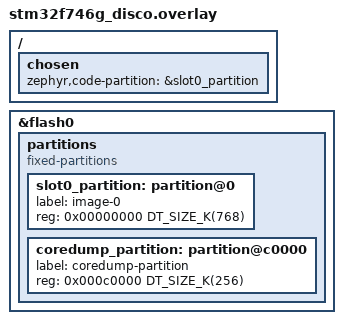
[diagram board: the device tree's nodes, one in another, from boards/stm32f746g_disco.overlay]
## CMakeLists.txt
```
cmake_minimum_required(VERSION 3.20.0)

if (EXISTS "${CMAKE_CURRENT_SOURCE_DIR}/credentials.conf")
    list(APPEND EXTRA_CONF_FILE "${CMAKE_CURRENT_SOURCE_DIR}/credentials.conf")
endif()

find_package(Zephyr REQUIRED HINTS $ENV{ZEPHYR_BASE})
project(stm32_cold_chain_monitor)

add_subdirectory(src/net ${CMAKE_CURRENT_BINARY_DIR}/src/net)

target_sources(app PRIVATE
        src/main.c
        src/fridge_monitor.c
        src/ui.c
        src/spotflow_logo.c
)
```

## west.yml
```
manifest:
  projects:
    # Zephyr RTOS - STMicroelectronics STM32F746G-DISCO
    - name: zephyr
      url: https://github.com/zephyrproject-rtos/zephyr
      revision: v4.4.0
      clone-depth: 1
      import:
        path-prefix: external
        name-allowlist:
          - cmsis
          - cmsis_6
          - hal_stm32
          - mbedtls
          - tf-psa-crypto
          - zcbor
          - lvgl

    - name: spotflow-device-sdk
      url: https://github.com/spotflow-io/device-sdk
      revision: main
      path: external/modules/lib/spotflow
```

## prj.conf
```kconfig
# Spotflow SDK
CONFIG_SPOTFLOW=y
CONFIG_SPOTFLOW_MODULE_DEFAULT_LOG_LEVEL=4

# Logging
CONFIG_LOG=y
CONFIG_LOG_BUFFER_SIZE=2048
CONFIG_LOG_RUNTIME_FILTERING=y
CONFIG_REQUIRES_FLOAT_PRINTF=y
CONFIG_LOG_FUNC_NAME_PREFIX_INF=y
CONFIG_LOG_FUNC_NAME_PREFIX_WRN=y
CONFIG_LOG_FUNC_NAME_PREFIX_ERR=y
CONFIG_SPOTFLOW_LOG_BACKEND_QUEUE_SIZE=16
CONFIG_SPOTFLOW_LOG_BUFFER_SIZE=256
CONFIG_SPOTFLOW_CBOR_LOG_MAX_LEN=512
CONFIG_HEAP_MEM_POOL_ADD_SIZE_SPOTFLOW_LOGGING=3072

# Metrics
CONFIG_SPOTFLOW_METRICS=y
CONFIG_SPOTFLOW_METRICS_SYSTEM=y
CONFIG_SPOTFLOW_METRICS_HEARTBEAT=y
CONFIG_SPOTFLOW_METRICS_HEARTBEAT_INTERVAL=60
CONFIG_HEAP_MEM_POOL_ADD_SIZE_SPOTFLOW_METRICS=6144

# Networking (Ethernet + DHCP; TLS/MQTT are pulled in by the Spotflow module)
CONFIG_NETWORKING=y
CONFIG_NET_MGMT=y
CONFIG_NET_MGMT_EVENT=y
CONFIG_NET_MGMT_EVENT_INFO=y
CONFIG_NET_CONFIG_AUTO_INIT=n
CONFIG_NET_CONNECTION_MANAGER=y
CONFIG_NET_DHCPV4=y
CONFIG_NET_IPV4=y
CONFIG_NET_IPV6=n
CONFIG_NET_TCP=y
CONFIG_NET_UDP=y

# Flash: enabled for the coredump partition backend (see boards/*.overlay).
#
# Spotflow config persistence (NVS/settings) is intentionally disabled on this
# board. The Spotflow config store initializes from the log backend before the
# kernel scheduler is running, and the STM32 QSPI flash that would hold the
# storage partition cannot service a blocking read that early (it returns
# -EDEADLK). Logs, metrics, and coredumps do not depend on persistence.
CONFIG_FLASH=y
CONFIG_FLASH_MAP=y
CONFIG_SPOTFLOW_SAMPLE_CONFIG_PERSISTENCE_FLASH=n

# Coredumps: captured to the internal-flash coredump partition on a fatal
# fault, then uploaded to Spotflow on the next boot over MQTT/TLS.
# CONFIG_SPOTFLOW_COREDUMPS selects DEBUG_COREDUMP, FLASH and REBOOT and
# defaults the backend to DEBUG_COREDUMP_BACKEND_FLASH_PARTITION. THREADS mode
# dumps thread stacks and metadata instead of the whole linker-defined RAM
# image, which keeps the dump well inside the 256 KiB partition.
CONFIG_SPOTFLOW_COREDUMPS=y
CONFIG_DEBUG_COREDUMP_THREADS_METADATA=y
CONFIG_DEBUG_COREDUMP_MEMORY_DUMP_THREADS=y
CONFIG_GPIO=y

# Constrain the application image to the code partition (first 768 KiB), leaving
# the last flash sector for coredumps (see boards/stm32f746g_disco.overlay).
CONFIG_USE_DT_CODE_PARTITION=y

# Local display: 4.3" LTDC LCD via LVGL v9 with FT5336 capacitive touch.
# The framebuffer lives in the external SDRAM (see the board devicetree).
CONFIG_DISPLAY=y
CONFIG_INPUT=y
CONFIG_LVGL=y
CONFIG_LV_Z_POINTER_INPUT=y
CONFIG_LV_USE_LABEL=y
CONFIG_LV_USE_BUTTON=y
CONFIG_LV_USE_IMAGE=y
CONFIG_LV_FONT_MONTSERRAT_14=y
CONFIG_LV_FONT_MONTSERRAT_28=y
CONFIG_LV_Z_MEM_POOL_SIZE=32768

# Keep LVGL's working buffers out of the scarce 256 KiB internal SRAM by placing
# both the object memory pool and the render buffers in the 8 MiB external SDRAM
# (the "SDRAM1" memory-region from the board devicetree).
CONFIG_LV_Z_MEMORY_POOL_ZEPHYR_REGION=y
CONFIG_LV_Z_MEMORY_POOL_ZEPHYR_REGION_NAME="SDRAM1"
CONFIG_LV_Z_BUFFER_ALLOC_STATIC=y
CONFIG_LV_Z_VDB_ZEPHYR_REGION=y
CONFIG_LV_Z_VDB_ZEPHYR_REGION_NAME="SDRAM1"

# Stack
CONFIG_MAIN_STACK_SIZE=4096
```

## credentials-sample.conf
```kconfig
# Copy this file to credentials.conf and fill in your values.
# credentials.conf is excluded from version control by .gitignore.
# This board connects over Ethernet, so no Wi-Fi credentials are needed.
CONFIG_SPOTFLOW_DEVICE_ID="cold-chain-monitor-001"
CONFIG_SPOTFLOW_INGEST_KEY=""
```

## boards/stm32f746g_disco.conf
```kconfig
# Log processing thread needs extra stack for the UART + Spotflow backends
CONFIG_LOG_PROCESS_THREAD_STACK_SIZE=4096
```

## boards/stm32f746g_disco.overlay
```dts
/*
 * Reserve the last 256 KiB sector of the STM32F746 internal flash (sector 7, at
 * offset 0xC0000) for Zephyr coredump storage, and constrain the application
 * image to the first 768 KiB (sectors 0-6).
 *
 * Internal flash is used rather than the QSPI NOR because coredumps are written
 * from the fatal-error handler, where the QSPI driver's IRQ-driven, blocking
 * transfers are unavailable. The STM32 internal flash controller programs
 * synchronously and works in that context.
 *
 * The split is sector-aligned: sectors 0-6 span 0x00000-0xC0000 (768 KiB) and
 * sector 7 spans 0xC0000-0x100000 (256 KiB).
 */

/ {
	chosen {
		zephyr,code-partition = &slot0_partition;
	};
};

&flash0 {
	partitions {
		compatible = "fixed-partitions";
		#address-cells = <1>;
		#size-cells = <1>;

		slot0_partition: partition@0 {
			label = "image-0";
			reg = <0x00000000 DT_SIZE_K(768)>;
		};

		coredump_partition: partition@c0000 {
			label = "coredump-partition";
			reg = <0x000c0000 DT_SIZE_K(256)>;
		};
	};
};
```

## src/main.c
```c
#include <errno.h>

#include <zephyr/drivers/gpio.h>
#include <zephyr/kernel.h>
#include <zephyr/logging/log.h>

#include "net.h"
#include "fridge_monitor.h"
#include "ui.h"

LOG_MODULE_REGISTER(main, LOG_LEVEL_INF);

#define SW0_NODE DT_ALIAS(sw0)
#if !DT_NODE_HAS_STATUS_OKAY(SW0_NODE)
#error "Unsupported board: sw0 devicetree alias is not defined"
#endif

static const struct gpio_dt_spec button = GPIO_DT_SPEC_GET_OR(SW0_NODE, gpios, { 0 });
static struct gpio_callback button_cb_data;

static void button_pressed(const struct device *dev, struct gpio_callback *cb, uint32_t pins)
{
	ARG_UNUSED(dev);
	ARG_UNUSED(cb);
	ARG_UNUSED(pins);

	LOG_WRN("User button pressed. Simulating a temperature excursion.");
	fridge_monitor_simulate_excursion();
}

static int prepare_button(void)
{
	int ret;

	if (!gpio_is_ready_dt(&button)) {
		LOG_ERR("Error: button device %s is not ready", button.port->name);
		return -EINVAL;
	}

	ret = gpio_pin_configure_dt(&button, GPIO_INPUT);
	if (ret != 0) {
		LOG_ERR("Error %d: failed to configure %s pin %d",
			ret, button.port->name, button.pin);
		return ret;
	}

	ret = gpio_pin_interrupt_configure_dt(&button, GPIO_INT_EDGE_TO_ACTIVE);
	if (ret != 0) {
		LOG_ERR("Error %d: failed to configure interrupt on %s pin %d",
			ret, button.port->name, button.pin);
		return ret;
	}

	gpio_init_callback(&button_cb_data, button_pressed, BIT(button.pin));
	gpio_add_callback(button.port, &button_cb_data);

	return 0;
}

int main(void)
{
	LOG_INF("STM32F746G-DISCO cold-chain fridge monitor starting");
	LOG_INF("Local display serves on-site staff; Spotflow gives the operations team remote visibility of the fleet.");

	int rc = prepare_button();
	if (rc != 0) {
		LOG_ERR("Failed to prepare button: %d", rc);
		return rc;
	}

	/* Allow the network interface driver to finish initialization. */
	k_sleep(K_SECONDS(1));
	spotflow_sample_net_init();

	rc = fridge_monitor_init();
	if (rc < 0) {
		LOG_ERR("Failed to initialize fridge monitor: %d", rc);
		return rc;
	}

	/* Bring up the local display on the LCD (runs in its own thread). */
	ui_start();

	while (true) {
		fridge_monitor_step();
		k_sleep(K_SECONDS(2));
	}

	return 0;
}
```

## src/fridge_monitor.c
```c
#include "fridge_monitor.h"

#include <zephyr/kernel.h>
#include <zephyr/logging/log.h>
#include <zephyr/random/random.h>

#include "metrics/spotflow_metrics_backend.h"

LOG_MODULE_REGISTER(fridge_monitor, LOG_LEVEL_INF);

/* Safe upper limit for a fresh-food / vaccine refrigerator. */
#define SAFE_MAX_CELSIUS 8.0f

/* ---- application metrics ---- */
static struct spotflow_metric_float *g_temperature_metric;
static struct spotflow_metric_int   *g_read_errors_metric;

/* ---- shared state for the local display ---- */
static float    g_last_temp   = 0.0f;
static uint32_t g_read_errors = 0;

/* ---- alarm / crash state ---- */

/*
 * Alarm callback type. In a real product this would be registered during
 * initialization based on the unit's configuration (loaded from NVS or
 * provisioned from the cloud). On this cabinet the callback was never
 * registered, because the unit was deployed as a display-only monitor that was
 * never wired to the alerting backend.
 *
 * The firmware calls the callback unconditionally whenever the cabinet leaves
 * its safe range: a classic null-function-pointer bug that faults at the worst
 * possible moment, exactly when a fridge warms up and the alarm should fire.
 */
typedef void (*alarm_fn_t)(float temp_celsius);

static alarm_fn_t g_alarm_callback = NULL; /* not registered on this unit */
static bool       g_excursion      = false;
static int        g_loop_count     = 0;

/* ---- helpers ---- */

static float rand_range(float min, float max)
{
	return min + ((float)(sys_rand32_get() % 1000) / 1000.0f) * (max - min);
}

/*
 * check_temperature: called every cycle.
 *
 * BUG: g_alarm_callback is NULL (alarm handler not registered on this unit).
 * This models a real pattern: a callback registered only on certain device
 * variants during initialization, but called from a shared processing path
 * without a null check.
 */
static void check_temperature(float temp_celsius)
{
	if (temp_celsius > SAFE_MAX_CELSIUS) {
		LOG_WRN("Cabinet temperature above safe limit: %.1f C (limit: %.1f C)",
			(double)temp_celsius, (double)SAFE_MAX_CELSIUS);
		/*
		 * Give the display one refresh to show the alarm state before the
		 * (buggy) handler runs, so on the LCD the fault reads as an alarm and
		 * reboot rather than an instant, unexplained screen blank.
		 */
		k_sleep(K_MSEC(1500));
		/* NULL dereference: fatal fault on next line */
		g_alarm_callback(temp_celsius);
	}
}

/* ---- public API ---- */

int fridge_monitor_init(void)
{
	int rc;

	g_loop_count = 0;
	g_excursion  = false;

	/*
	 * The probe is read every 2 s, but the value is aggregated on the device
	 * and sent once a minute as min / max / mean / count. That is what a
	 * cold-chain log needs, and it keeps the outbound queue small when the
	 * network is down. PT0S (no aggregation) would send 30 messages a minute.
	 */
	rc = spotflow_register_metric_float(
		"temperature_celsius",
		SPOTFLOW_AGG_INTERVAL_1MIN,
		&g_temperature_metric);
	if (rc < 0) {
		LOG_ERR("Failed to register temperature_celsius metric: %d", rc);
		return rc;
	}

	rc = spotflow_register_metric_int(
		"read_errors",
		SPOTFLOW_AGG_INTERVAL_NONE,
		&g_read_errors_metric);
	if (rc < 0) {
		LOG_ERR("Failed to register read_errors metric: %d", rc);
		return rc;
	}

	LOG_INF("Cold-chain monitor ready. Press the user button (or the on-screen "
		"button) to simulate a temperature excursion.");
	return 0;
}

void fridge_monitor_step(void)
{
	++g_loop_count;

	/*
	 * Simulate the cabinet temperature. Normally 2-6 C. After an excursion is
	 * triggered (door left open / compressor fault) the cabinet warms up
	 * gradually, about 1.5 C per 2 s cycle, so the climb past the 8 C limit is
	 * visible on the LCD for a few seconds before the alarm faults.
	 */
	float temp;
	if (g_excursion) {
		temp = g_last_temp + rand_range(1.2f, 1.8f);
		if (temp > 13.0f) {
			temp = 13.0f;
		}
	} else {
		temp = rand_range(2.0f, 6.0f);
	}
	g_last_temp = temp;

	int rc = spotflow_report_metric_float(g_temperature_metric, temp);
	if (rc < 0) {
		LOG_ERR("Failed to report temperature_celsius: %d", rc);
	}

	LOG_INF("Cabinet temperature: %.1f C", (double)temp);

	/* Simulate an occasional I2C read timeout from the temperature probe. */
	if ((g_loop_count % 9) == 0) {
		LOG_WRN("Temperature probe I2C read timeout, retrying");
		++g_read_errors;
		rc = spotflow_report_event(g_read_errors_metric);
		if (rc < 0) {
			LOG_ERR("Failed to report read_errors: %d", rc);
		}
	}

	/* The alarm path runs every cycle; only an excursion exceeds the limit. */
	check_temperature(temp);
}

void fridge_monitor_simulate_excursion(void)
{
	LOG_WRN("Temperature excursion simulated (door left open). Cabinet warming "
		"past the safe limit.");
	g_excursion = true;
}

float fridge_monitor_last_temp(void)
{
	return g_last_temp;
}

uint32_t fridge_monitor_read_errors(void)
{
	return g_read_errors;
}

bool fridge_monitor_in_excursion(void)
{
	return g_excursion;
}
```

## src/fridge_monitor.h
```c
#ifndef STM32_COLD_CHAIN_FRIDGE_MONITOR_H
#define STM32_COLD_CHAIN_FRIDGE_MONITOR_H

#include <stdbool.h>
#include <stdint.h>

int  fridge_monitor_init(void);
void fridge_monitor_step(void);

/* Simulate a temperature excursion (a door left open or a compressor fault)
 * that drives the cabinet past its safe limit. Wired to the user button and the
 * on-screen button. */
void fridge_monitor_simulate_excursion(void);

/* Shared state, read by the local LVGL display. */
float    fridge_monitor_last_temp(void);
uint32_t fridge_monitor_read_errors(void);
bool     fridge_monitor_in_excursion(void);

#endif /* STM32_COLD_CHAIN_FRIDGE_MONITOR_H */
```

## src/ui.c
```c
#include "ui.h"

#include <stdio.h>

#include <zephyr/device.h>
#include <zephyr/devicetree.h>
#include <zephyr/drivers/display.h>
#include <zephyr/kernel.h>
#include <zephyr/logging/log.h>
#include <zephyr/net/net_if.h>
#include <zephyr/net/net_ip.h>

#include <lvgl.h>

#include "fridge_monitor.h"

LOG_MODULE_REGISTER(ui, LOG_LEVEL_INF);

/* Spotflow logo mark, generated from the official logo.svg (see spotflow_logo.c). */
extern const lv_image_dsc_t spotflow_logo;

#define UI_THREAD_STACK_SIZE 4096
#define UI_THREAD_PRIORITY   6
#define UI_REFRESH_MS        500

static lv_obj_t *temp_label;
static lv_obj_t *uptime_label;
static lv_obj_t *ip_label;
static lv_obj_t *errors_label;
static lv_obj_t *status_label;
static lv_obj_t *alarm_label;

/* Cabinet safe upper limit, mirrored from fridge_monitor.c for display state. */
#define UI_SAFE_MAX_CELSIUS 8.0f

/*
 * On-screen "SIMULATE EXCURSION" button. Drives the same temperature excursion
 * as the physical USER button, so the crash-to-Spotflow demo can be run entirely
 * from the touchscreen.
 */
static void crash_btn_cb(lv_event_t *e)
{
	ARG_UNUSED(e);
	LOG_WRN("On-screen button pressed. Simulating a temperature excursion.");
	fridge_monitor_simulate_excursion();
}

static void build_ui(void)
{
	lv_obj_t *scr = lv_screen_active();
	lv_obj_set_style_bg_color(scr, lv_color_hex(0x0b1f33), LV_PART_MAIN);

	/* Centered Spotflow logo. */
	lv_obj_t *logo = lv_image_create(scr);
	lv_image_set_src(logo, &spotflow_logo);
	lv_obj_align(logo, LV_ALIGN_TOP_MID, 0, 12);

	/* Tagline below the logo. */
	lv_obj_t *tagline = lv_label_create(scr);
	lv_label_set_text(tagline, "Firmware Observability. Automated.");
	lv_obj_set_style_text_color(tagline, lv_color_hex(0x8fa3b8), 0);
	lv_obj_align(tagline, LV_ALIGN_TOP_MID, 0, 62);

	temp_label = lv_label_create(scr);
	lv_obj_set_style_text_font(temp_label, &lv_font_montserrat_28, 0);
	lv_obj_set_style_text_color(temp_label, lv_color_hex(0x35d07f), 0);
	lv_obj_align(temp_label, LV_ALIGN_TOP_LEFT, 12, 92);
	lv_label_set_text(temp_label, "--.- C");

	uptime_label = lv_label_create(scr);
	lv_obj_set_style_text_color(uptime_label, lv_color_hex(0xcfd8e3), 0);
	lv_obj_align(uptime_label, LV_ALIGN_TOP_LEFT, 12, 134);

	ip_label = lv_label_create(scr);
	lv_obj_set_style_text_color(ip_label, lv_color_hex(0xcfd8e3), 0);
	lv_obj_align(ip_label, LV_ALIGN_TOP_LEFT, 12, 160);

	errors_label = lv_label_create(scr);
	lv_obj_set_style_text_color(errors_label, lv_color_hex(0xcfd8e3), 0);
	lv_obj_align(errors_label, LV_ALIGN_TOP_LEFT, 12, 186);

	status_label = lv_label_create(scr);
	lv_obj_set_style_text_color(status_label, lv_color_hex(0xffcc00), 0);
	lv_obj_align(status_label, LV_ALIGN_TOP_LEFT, 12, 212);
	lv_label_set_text(status_label, "Network: waiting for DHCP...");

	lv_obj_t *device = lv_label_create(scr);
	lv_label_set_text(device, "Device: cold-chain-monitor-001");
	lv_obj_set_style_text_color(device, lv_color_hex(0x5b6f84), 0);
	lv_obj_align(device, LV_ALIGN_BOTTOM_LEFT, 12, -14);

	/*
	 * Alarm banner, top-right (free area above the button). Hidden in normal
	 * operation; shown amber while the cabinet is warming and red once it is
	 * above the safe limit, so a button press has visible on-screen feedback
	 * before the fault.
	 */
	alarm_label = lv_label_create(scr);
	lv_obj_set_style_text_font(alarm_label, &lv_font_montserrat_28, 0);
	lv_obj_set_style_text_color(alarm_label, lv_color_hex(0xffffff), 0);
	lv_obj_set_style_bg_color(alarm_label, lv_color_hex(0xd21f1f), 0);
	lv_obj_set_style_bg_opa(alarm_label, LV_OPA_COVER, 0);
	lv_obj_set_style_pad_all(alarm_label, 8, 0);
	lv_obj_set_style_radius(alarm_label, 6, 0);
	lv_obj_set_style_text_align(alarm_label, LV_TEXT_ALIGN_CENTER, 0);
	lv_obj_align(alarm_label, LV_ALIGN_TOP_RIGHT, -14, 92);
	lv_obj_add_flag(alarm_label, LV_OBJ_FLAG_HIDDEN);

	lv_obj_t *btn = lv_button_create(scr);
	lv_obj_set_size(btn, 200, 64);
	lv_obj_align(btn, LV_ALIGN_BOTTOM_RIGHT, -14, -14);
	lv_obj_set_style_bg_color(btn, lv_color_hex(0xd21f1f), 0);
	lv_obj_add_event_cb(btn, crash_btn_cb, LV_EVENT_CLICKED, NULL);

	lv_obj_t *btn_label = lv_label_create(btn);
	lv_label_set_text(btn_label, "SIMULATE EXCURSION");
	lv_obj_set_style_text_color(btn_label, lv_color_hex(0xffffff), 0);
	lv_obj_center(btn_label);
}

static void update_ui(void)
{
	char buf[40];

	float temp = fridge_monitor_last_temp();
	bool excursion = fridge_monitor_in_excursion();

	snprintf(buf, sizeof(buf), "%.1f C", (double)temp);
	lv_label_set_text(temp_label, buf);

	/*
	 * Colour the temperature and raise the alarm banner so a triggered excursion
	 * is obvious on the LCD: green in normal operation, amber while warming,
	 * red once the cabinet is above its safe limit.
	 */
	if (excursion && temp > UI_SAFE_MAX_CELSIUS) {
		lv_obj_set_style_text_color(temp_label, lv_color_hex(0xff5555), 0);
		lv_label_set_text(alarm_label, "ALARM\nAbove safe limit");
		lv_obj_set_style_bg_color(alarm_label, lv_color_hex(0xd21f1f), 0);
		lv_obj_clear_flag(alarm_label, LV_OBJ_FLAG_HIDDEN);
	} else if (excursion) {
		lv_obj_set_style_text_color(temp_label, lv_color_hex(0xffcc00), 0);
		lv_label_set_text(alarm_label, "EXCURSION\nCabinet warming");
		lv_obj_set_style_bg_color(alarm_label, lv_color_hex(0xb26a00), 0);
		lv_obj_clear_flag(alarm_label, LV_OBJ_FLAG_HIDDEN);
	} else {
		lv_obj_set_style_text_color(temp_label, lv_color_hex(0x35d07f), 0);
		lv_obj_add_flag(alarm_label, LV_OBJ_FLAG_HIDDEN);
	}

	uint32_t up = (uint32_t)(k_uptime_get() / 1000);
	snprintf(buf, sizeof(buf), "Uptime: %02u:%02u:%02u",
		 up / 3600U, (up % 3600U) / 60U, up % 60U);
	lv_label_set_text(uptime_label, buf);

	snprintf(buf, sizeof(buf), "Probe errors: %u", fridge_monitor_read_errors());
	lv_label_set_text(errors_label, buf);

	char ipstr[NET_IPV4_ADDR_LEN] = "-";
	struct net_if *iface = net_if_get_default();
	bool link = (iface != NULL) && net_if_is_carrier_ok(iface);
	struct in_addr *addr = NULL;

	if (link) {
		addr = net_if_ipv4_get_global_addr(iface, NET_ADDR_PREFERRED);
		if (addr != NULL) {
			net_addr_ntop(AF_INET, addr, ipstr, sizeof(ipstr));
		}
	}
	snprintf(buf, sizeof(buf), "IP: %s", ipstr);
	lv_label_set_text(ip_label, buf);

	/*
	 * The SDK has no public "MQTT connected" query, so the display reports the
	 * link and address state it can see for itself. Carrier (NET_IF_LOWER_UP)
	 * tracks the Ethernet cable, so unplugging it flips the status to "offline".
	 */
	if (!link) {
		lv_label_set_text(status_label, "Network: offline");
		lv_obj_set_style_text_color(status_label, lv_color_hex(0xd21f1f), 0);
	} else if (addr == NULL) {
		lv_label_set_text(status_label, "Network: waiting for DHCP...");
		lv_obj_set_style_text_color(status_label, lv_color_hex(0xffcc00), 0);
	} else {
		lv_label_set_text(status_label, "Network: online");
		lv_obj_set_style_text_color(status_label, lv_color_hex(0x35d07f), 0);
	}
}

static void ui_thread_entry(void *a, void *b, void *c)
{
	ARG_UNUSED(a);
	ARG_UNUSED(b);
	ARG_UNUSED(c);

	const struct device *display_dev = DEVICE_DT_GET(DT_CHOSEN(zephyr_display));

	/* The display initializes at APPLICATION level; give it a moment if needed. */
	for (int i = 0; i < 50 && !device_is_ready(display_dev); i++) {
		k_sleep(K_MSEC(20));
	}
	if (!device_is_ready(display_dev)) {
		LOG_ERR("Display device not ready; local panel disabled");
		return;
	}

	build_ui();
	display_blanking_off(display_dev);
	LOG_INF("Cold-chain monitor display ready on the LTDC LCD");

	uint32_t last_update = 0;
	while (true) {
		uint32_t now = k_uptime_get_32();
		if ((now - last_update) >= UI_REFRESH_MS) {
			update_ui();
			last_update = now;
		}
		lv_timer_handler();
		k_sleep(K_MSEC(10));
	}
}

K_THREAD_STACK_DEFINE(ui_stack, UI_THREAD_STACK_SIZE);
static struct k_thread ui_thread;

void ui_start(void)
{
	k_thread_create(&ui_thread, ui_stack, K_THREAD_STACK_SIZEOF(ui_stack),
			ui_thread_entry, NULL, NULL, NULL,
			UI_THREAD_PRIORITY, 0, K_NO_WAIT);
	k_thread_name_set(&ui_thread, "ui");
}
```

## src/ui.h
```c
#ifndef STM32_COLD_CHAIN_UI_H
#define STM32_COLD_CHAIN_UI_H

/* Start the local LVGL display on the LTDC LCD (spawns the UI thread). */
void ui_start(void);

#endif /* STM32_COLD_CHAIN_UI_H */
```
